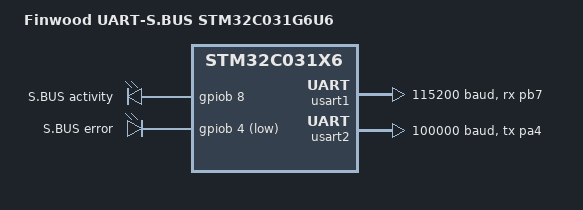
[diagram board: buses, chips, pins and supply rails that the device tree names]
/*
 * SPDX-License-Identifier: Apache-2.0
 */

/dts-v1/;
#include <st/c0/stm32c031X6.dtsi>
#include <st/c0/stm32c031g(4-6)ux-pinctrl.dtsi>
#include <zephyr/dt-bindings/gpio/gpio.h>

/ {
	model = "Finwood UART-S.BUS STM32C031G6U6";
	compatible = "finwood,sbus-c031g6";

	chosen {
		zephyr,sram = &sram0;
		zephyr,flash = &flash0;
	};

	leds {
		compatible = "gpio-leds";

		led_green: led_0 {
			gpios = <&gpiob 8 GPIO_ACTIVE_HIGH>;
			label = "S.BUS activity";
		};

		led_red: led_1 {
			gpios = <&gpiob 4 (GPIO_OPEN_DRAIN | GPIO_ACTIVE_LOW)>;
			label = "S.BUS error";
		};
	};

	aliases {
		uart-in = &usart1;
		sbus-out = &usart2;
		led0 = &led_green;
		led1 = &led_red;
	};
};

/* Cheap board: no HSE/LSE crystals. SoC HSI is 48 MHz, hsi-div = 1. */
&clk_hsi {
	status = "okay";
};

&rcc {
	clocks = <&clk_hsi>;
	clock-frequency = <DT_FREQ_M(48)>;
	ahb-prescaler = <1>;
	apb1-prescaler = <1>;
};

/*
 * USART1 IRQ 27 and USART2 IRQ 28 share NVIC priority 0: the sample asserts
 * equal priorities so RX cannot starve TX mid-byte (and vice versa).
 */
&usart1 {
	pinctrl-0 = <&usart1_rx_pb7>;
	pinctrl-names = "default";
	current-speed = <115200>;
	fifo-enable;
	interrupts = <27 0>;
	status = "okay";
};

/* USART2 TX-only inverted S.BUS on PA4 (not PA14/SWCLK). */
&usart2 {
	pinctrl-0 = <&usart2_tx_pa4>;
	pinctrl-names = "default";
	current-speed = <100000>;
	parity = "even";
	stop-bits = "2";
	tx-invert;
	fifo-enable;
	interrupts = <28 0>;
	status = "okay";
};
